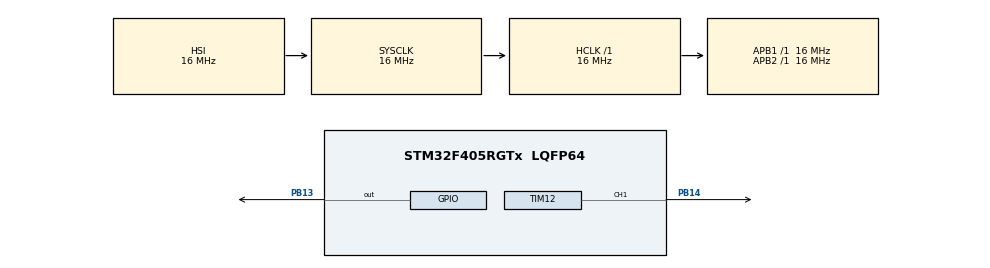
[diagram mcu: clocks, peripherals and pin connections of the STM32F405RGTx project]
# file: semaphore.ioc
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Mcu.Family=STM32F4
Mcu.Name=STM32F405RGTx
Mcu.Package=LQFP64
NVIC.PriorityGroup=NVIC_PRIORITYGROUP_4
NVIC.TIM6_DAC_IRQn=true\:15\:0\:false\:false\:true\:false\:true\:true
NVIC.TimeBase=TIM6_DAC_IRQn
NVIC.TimeBaseIP=TIM6
PB13.Signal=GPIO_Output
PB14.Signal=S_TIM12_CH1
ProjectManager.HeapSize=0x200
ProjectManager.StackSize=0x400
ProjectManager.TargetToolchain=STM32CubeIDE
RCC.AHBFreq_Value=16000000
RCC.APB1Freq_Value=16000000
RCC.APB2Freq_Value=16000000
RCC.CortexFreq_Value=16000000
RCC.HSE_VALUE=25000000
RCC.HSI_VALUE=16000000
RCC.LSE_VALUE=32768
RCC.SYSCLKFreq_VALUE=16000000
RCC.VCOOutputFreq_Value=192000000
SH.S_TIM12_CH1.0=TIM12_CH1,PWM Generation1 CH1
TIM12.Channel-PWM\ Generation1\ CH1=TIM_CHANNEL_1
VP_SYS_VS_tim6.Mode=TIM6
board=custom

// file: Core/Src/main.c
/* USER CODE BEGIN Header */
/**
  ******************************************************************************
  * @file           : main.c
  * @brief          : Main program body
  ******************************************************************************
  * @attention
  *
  * Copyright (c) 2025 STMicroelectronics.
  * All rights reserved.
  *
  * This software is licensed under terms that can be found in the LICENSE file
  * in the root directory of this software component.
  * If no LICENSE file comes with this software, it is provided AS-IS.
  *
  ******************************************************************************
  */
/* USER CODE END Header */
#include "main.h"

/* USER CODE BEGIN Includes */
#include"FreeRTOS.h"
#include"task.h"

/* USER CODE END Includes */

/* USER CODE BEGIN PTD */
#include"semphr.h"
/* USER CODE END PTD */

SemaphoreHandle_t xSemaphore = NULL;
TIM_HandleTypeDef htim12;

void SystemClock_Config(void);
static void MX_GPIO_Init(void);
static void MX_TIM12_Init(void);
/* USER CODE BEGIN PFP */
void blink(void *pvParameters);
void pwm(void *pvParameters);
/* USER CODE END PFP */

void pwm(void *pvParameters) {

	for (;;) {

				HAL_TIM_PWM_Start(&htim12, TIM_CHANNEL_1);

					TIM12->CCR1 = 5000;
					vTaskDelay(pdMS_TO_TICKS(100));
					TIM12->CCR1 = 3000;
					vTaskDelay(pdMS_TO_TICKS(100));
					TIM12->CCR1 = 1500;
					vTaskDelay(pdMS_TO_TICKS(100));
					TIM12->CCR1 = 800;
					vTaskDelay(pdMS_TO_TICKS(100));
					TIM12->CCR1 = 200;
					vTaskDelay(pdMS_TO_TICKS(100));

				xSemaphoreGive(xSemaphore);
			}
	vTaskDelay(pdMS_TO_TICKS(500));
}

void blink(void *pvParameters) {
	GPIO_InitTypeDef GPIO_InitStruct = { 0 };

	/* GPIO Ports Clock Enable */
//	__HAL_RCC_GPIOB_CLK_ENABLE();
//
//	HAL_GPIO_DeInit(GPIOB, GPIO_PIN_14);
//	HAL_GPIO_WritePin(GPIOB, GPIO_PIN_14, GPIO_PIN_RESET);
//
//	GPIO_InitStruct.Pin = GPIO_PIN_14;
//	GPIO_InitStruct.Mode = GPIO_MODE_OUTPUT_PP;
//	GPIO_InitStruct.Pull = GPIO_NOPULL;
//	GPIO_InitStruct.Speed = GPIO_SPEED_FREQ_LOW;
//	HAL_GPIO_Init(GPIOB, &GPIO_InitStruct);
//
//	GPIOB->MODER|=(0X1<<28);
	for (;;) {
		if (xSemaphore != NULL) {
			/* See if we can obtain the semaphore. If the semaphore is not
			 available wait 10 ticks to see if it becomes free. */
			if ( xSemaphoreTake( xSemaphore, ( TickType_t ) 10 ) == pdTRUE) {
				/* We were able to obtain the semaphore and can now access the
				 shared resource. */
				//MX_GPIO_Init();
				HAL_GPIO_WritePin(GPIOB, GPIO_PIN_13, 0);
				vTaskDelay(pdMS_TO_TICKS(100));
				HAL_GPIO_WritePin(GPIOB, GPIO_PIN_13, 1);
				vTaskDelay(pdMS_TO_TICKS(100));

				/* We have finished accessing the shared resource. Release the
				 semaphore. */
				//xSemaphoreGive(xSemaphore);
			}

		}
	}
}

int main() {
	HAL_Init();
	SystemClock_Config();
	MX_GPIO_Init();
	MX_TIM12_Init();

	xSemaphore = xSemaphoreCreateBinary();

	if (xSemaphore != NULL) {
		xSemaphoreGive(xSemaphore);  // Make the semaphore available initially
	}

	xTaskCreate(pwm, "PWM_Task", 128, NULL, 2, NULL);
	xTaskCreate(blink, "Blink_Task", 128, NULL, 1, NULL);

	vTaskStartScheduler();

	while (1) {
		// Should never reach here
	}
}

void SystemClock_Config(void)
{
  RCC_OscInitTypeDef RCC_OscInitStruct = {0};
  RCC_ClkInitTypeDef RCC_ClkInitStruct = {0};

  /** Configure the main internal regulator output voltage
  */
  __HAL_RCC_PWR_CLK_ENABLE();
  __HAL_PWR_VOLTAGESCALING_CONFIG(PWR_REGULATOR_VOLTAGE_SCALE1);

  /** Initializes the RCC Oscillators according to the specified parameters
  * in the RCC_OscInitTypeDef structure.
  */
  RCC_OscInitStruct.OscillatorType = RCC_OSCILLATORTYPE_HSI;
  RCC_OscInitStruct.HSIState = RCC_HSI_ON;
  RCC_OscInitStruct.HSICalibrationValue = RCC_HSICALIBRATION_DEFAULT;
  RCC_OscInitStruct.PLL.PLLState = RCC_PLL_NONE;
  if (HAL_RCC_OscConfig(&RCC_OscInitStruct) != HAL_OK)
  {
    Error_Handler();
  }

  /** Initializes the CPU, AHB and APB buses clocks
  */
  RCC_ClkInitStruct.ClockType = RCC_CLOCKTYPE_HCLK|RCC_CLOCKTYPE_SYSCLK
                              |RCC_CLOCKTYPE_PCLK1|RCC_CLOCKTYPE_PCLK2;
  RCC_ClkInitStruct.SYSCLKSource = RCC_SYSCLKSOURCE_HSI;
  RCC_ClkInitStruct.AHBCLKDivider = RCC_SYSCLK_DIV1;
  RCC_ClkInitStruct.APB1CLKDivider = RCC_HCLK_DIV1;
  RCC_ClkInitStruct.APB2CLKDivider = RCC_HCLK_DIV1;

  if (HAL_RCC_ClockConfig(&RCC_ClkInitStruct, FLASH_LATENCY_0) != HAL_OK)
  {
    Error_Handler();
  }
}

static void MX_TIM12_Init(void)
{

  TIM_OC_InitTypeDef sConfigOC = {0};

  htim12.Instance = TIM12;
  htim12.Init.Prescaler = 1600-1;
  htim12.Init.CounterMode = TIM_COUNTERMODE_UP;
  htim12.Init.Period = 10000-1;
  htim12.Init.ClockDivision = TIM_CLOCKDIVISION_DIV1;
  htim12.Init.AutoReloadPreload = TIM_AUTORELOAD_PRELOAD_DISABLE;
  if (HAL_TIM_PWM_Init(&htim12) != HAL_OK)
  {
    Error_Handler();
  }
  sConfigOC.OCMode = TIM_OCMODE_PWM1;
  sConfigOC.Pulse = 0;
  sConfigOC.OCPolarity = TIM_OCPOLARITY_HIGH;
  sConfigOC.OCFastMode = TIM_OCFAST_DISABLE;
  if (HAL_TIM_PWM_ConfigChannel(&htim12, &sConfigOC, TIM_CHANNEL_1) != HAL_OK)
  {
    Error_Handler();
  }
  HAL_TIM_MspPostInit(&htim12);

}

static void MX_GPIO_Init(void)
{
  GPIO_InitTypeDef GPIO_InitStruct = {0};

  /* GPIO Ports Clock Enable */
  __HAL_RCC_GPIOB_CLK_ENABLE();

  /*Configure GPIO pin Output Level */
  HAL_GPIO_WritePin(GPIOB, GPIO_PIN_13, GPIO_PIN_RESET);

  /*Configure GPIO pin : PB13 */
  GPIO_InitStruct.Pin = GPIO_PIN_13;
  GPIO_InitStruct.Mode = GPIO_MODE_OUTPUT_PP;
  GPIO_InitStruct.Pull = GPIO_NOPULL;
  GPIO_InitStruct.Speed = GPIO_SPEED_FREQ_LOW;
  HAL_GPIO_Init(GPIOB, &GPIO_InitStruct);

}

void HAL_TIM_PeriodElapsedCallback(TIM_HandleTypeDef *htim)
{
  if (htim->Instance == TIM6) {
    HAL_IncTick();
  }
}

void Error_Handler(void)
{
	__disable_irq();
	while (1) {
	}
}
